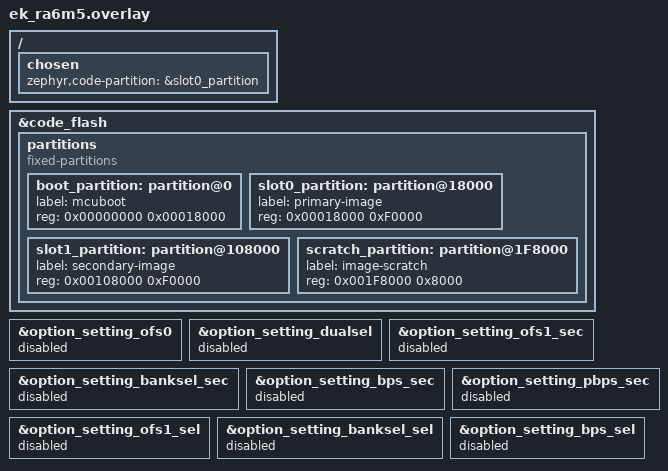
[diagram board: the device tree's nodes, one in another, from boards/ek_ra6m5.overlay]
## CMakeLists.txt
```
cmake_minimum_required(VERSION 3.20.0)
find_package(Zephyr REQUIRED HINTS $ENV{ZEPHYR_BASE})
project(lvd0_test)

target_sources(app PRIVATE src/main.c)

if(CONFIG_BOOTLOADER_MCUBOOT)
  set(signed_hex ${ZEPHYR_BINARY_DIR}/zephyr.signed.hex)
  set(signed_confirmed_hex ${ZEPHYR_BINARY_DIR}/zephyr.signed.confirmed.hex)

  dt_nodelabel(slot0_node NODELABEL "slot0_partition" REQUIRED)
  dt_nodelabel(slot1_node NODELABEL "slot1_partition" REQUIRED)

  dt_reg_addr(slot0_address PATH ${slot0_node})
  dt_reg_addr(slot1_address PATH ${slot1_node})
  
  math(EXPR slot1_offset "${slot1_address} - ${slot0_address}" OUTPUT_FORMAT HEXADECIMAL)

  add_custom_target(bank_images ALL
    COMMAND ${CMAKE_COMMAND} -E copy ${signed_hex} ${ZEPHYR_BINARY_DIR}/app_bank0.hex
    COMMAND ${CMAKE_OBJCOPY} -I ihex -O ihex --change-addresses ${slot1_offset}
            ${signed_hex} ${ZEPHYR_BINARY_DIR}/app_bank1.hex
    COMMAND ${CMAKE_COMMAND} -E copy ${signed_confirmed_hex} ${ZEPHYR_BINARY_DIR}/app_bank0_confirmed.hex
    COMMAND ${CMAKE_OBJCOPY} -I ihex -O ihex --change-addresses ${slot1_offset}
            ${signed_confirmed_hex} ${ZEPHYR_BINARY_DIR}/app_bank1_confirmed.hex
  )
  add_dependencies(bank_images ${logical_target_for_zephyr_elf})
endif()
```

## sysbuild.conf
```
SB_CONFIG_BOOTLOADER_MCUBOOT=y
SB_CONFIG_MCUBOOT_MODE_SWAP_SCRATCH=y
SB_CONFIG_BOOT_SIGNATURE_TYPE_ECDSA_P256=y
```

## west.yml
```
manifest:
  remotes:
    - name: P-Harwood
      url-base: https://github.com/P-Harwood

  projects:
    - name: zephyr
      remote: P-Harwood
      repo-path: zephyr_Exp
      revision: Bank_pin_v1
      clone-depth: 1
      import:
        name-allowlist:
          - cmsis_6
          - hal_renesas

    - name: mcuboot
      remote: P-Harwood
      repo-path: mcuboot
      revision: ra6m5-erase-size-v2
      path: bootloader/mcuboot
      
  self:
    path: applications/lvd_db
```

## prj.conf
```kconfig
CONFIG_BOOTLOADER_MCUBOOT=y
CONFIG_FLASH=y
CONFIG_IMG_MANAGER=y
CONFIG_MCUBOOT_IMG_MANAGER=y
CONFIG_STREAM_FLASH=y
CONFIG_PRINTK=y
CONFIG_FLASH_MAP=y
CONFIG_MCUBOOT_EXTRA_IMGTOOL_ARGS="--pad"
CONFIG_MCUBOOT_GENERATE_CONFIRMED_IMAGE=y
```

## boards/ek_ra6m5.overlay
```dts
/ {
    chosen {
        zephyr,code-partition = &slot0_partition;
    };
};
&code_flash {
    partitions {
        compatible = "fixed-partitions";
        #address-cells = <1>;
        #size-cells = <1>;
        boot_partition: partition@0 {
            label = "mcuboot";
            reg = <0x00000000 0x00018000>;
        };
        slot0_partition: partition@18000 {
            label = "primary-image";
            reg = <0x00018000 0xF0000>;
        };
        slot1_partition: partition@108000 {
            label = "secondary-image";
            reg = <0x00108000 0xF0000>;
        };
        scratch_partition: partition@1F8000 {
            label = "image-scratch";
            reg = <0x001F8000 0x8000>;
        };
    };
};
&option_setting_ofs0        { status = "disabled"; };
&option_setting_dualsel     { status = "disabled"; };
&option_setting_ofs1_sec    { status = "disabled"; };
&option_setting_banksel_sec { status = "disabled"; };
&option_setting_bps_sec     { status = "disabled"; };
&option_setting_pbps_sec    { status = "disabled"; };
&option_setting_ofs1_sel    { status = "disabled"; };
&option_setting_banksel_sel { status = "disabled"; };
&option_setting_bps_sel     { status = "disabled"; };
```

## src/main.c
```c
#include <zephyr/kernel.h>
#include <zephyr/sys/printk.h>
#include <zephyr/sys/sys_io.h>
#include <zephyr/dfu/mcuboot.h>


#define OFS0_ADDR     0x0100A100U
#define DUALSEL_ADDR  0x0100A110U
#define OFS1_ADDR     0x0100A180U
#define OFS1_SEC_ADDR 0x0100A200U
#define OFS1_SEL_ADDR 0x0100A280U


#define OFS1_VDSEL1_SHIFT   0
#define OFS1_VDSEL1_MASK    0x3
#define OFS1_LVDAS_SHIFT    2
#define OFS1_HOCOEN_SHIFT   8
#define OFS1_HOCOFRQ1_SHIFT 9
#define OFS1_HOCOFRQ1_MASK  0x3

static int iterations_until_confirm_check = 5;

static void print_word(const char *name, uint32_t addr)
{
	printk("%-9s @0x%08x = 0x%08x\n", name, addr, sys_read32(addr));
}

static void print_ofs1(const char *name, uint32_t addr)
{
	uint32_t value = sys_read32(addr);

	uint32_t vdsel1   = (value >> OFS1_VDSEL1_SHIFT)   & OFS1_VDSEL1_MASK;
	uint32_t lvdas    = (value >> OFS1_LVDAS_SHIFT)    & 0x1;
	uint32_t hocoen   = (value >> OFS1_HOCOEN_SHIFT)   & 0x1;
	uint32_t hocofrq1 = (value >> OFS1_HOCOFRQ1_SHIFT) & OFS1_HOCOFRQ1_MASK;

	printk("%-9s @0x%08x = 0x%08x  VDSEL1=%u LVDAS=%u HOCOEN=%u HOCOFRQ1=%u\n",
	       name, addr, value, vdsel1, lvdas, hocoen, hocofrq1);
}

int main(void)
{



	printk("--- RA6M5 option-setting memory ---\n");

	print_word("OFS0", OFS0_ADDR);
	print_word("DUALSEL", DUALSEL_ADDR);

	print_ofs1("OFS1", OFS1_ADDR);
	print_ofs1("OFS1_SEC", OFS1_SEC_ADDR);
	print_ofs1("OFS1_SEL", OFS1_SEL_ADDR); 

	while(true){



		if (iterations_until_confirm_check > 0){
			printk("Iterations until image confirmation: %d\n", iterations_until_confirm_check--);
		}

		else if(iterations_until_confirm_check ==0){

			if (!boot_is_img_confirmed() ) {

				int img_cnf = boot_write_img_confirmed();

				if (img_cnf) {
					printk("confirm failed (%d) - will revert on reboot\n", img_cnf);
				} else {
					printk("image confirmed - now permanent\n");
				}

			}
			else{
				printk("Image already confirmed\n");
			}

		}

		else{
        	printk("Running loop on an new image.\n");
		}


        k_msleep(1000);
    }

	return 0;
}
```
